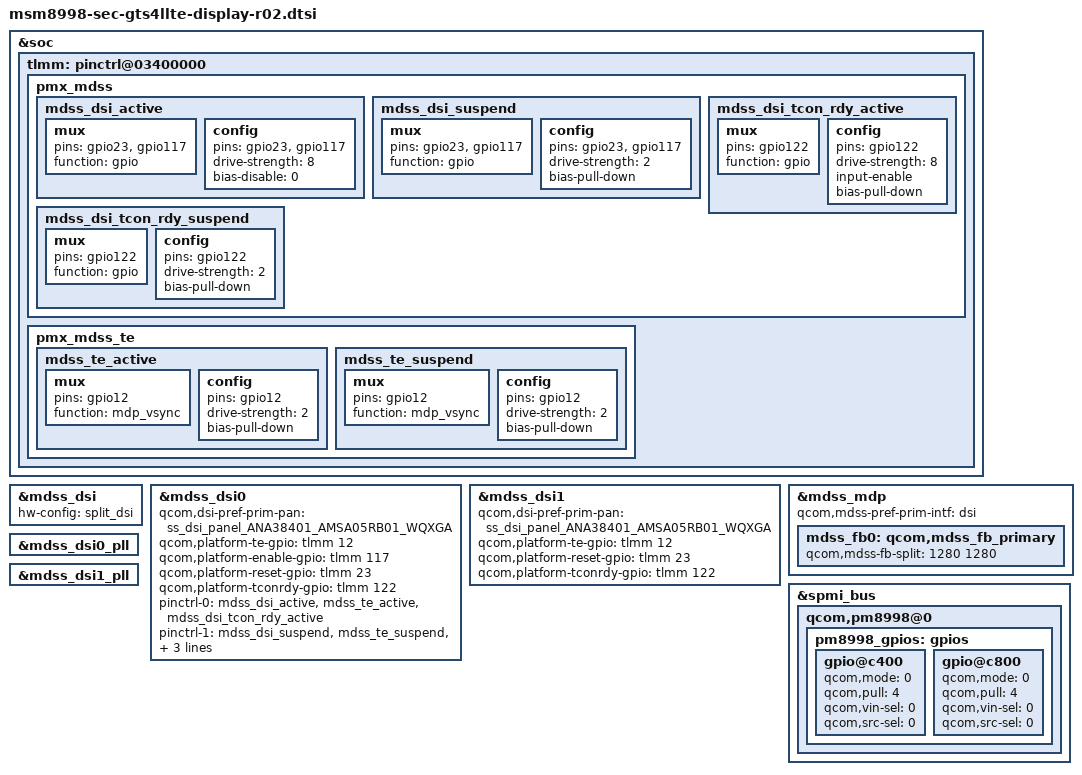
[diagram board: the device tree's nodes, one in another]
/* Copyright (c) 2016, The Linux Foundation. All rights reserved.
 *
 * This program is free software; you can redistribute it and/or modify
 * it under the terms of the GNU General Public License version 2 and
 * only version 2 as published by the Free Software Foundation.
 *
 * This program is distributed in the hope that it will be useful,
 * but WITHOUT ANY WARRANTY; without even the implied warranty of
 * MERCHANTABILITY or FITNESS FOR A PARTICULAR PURPOSE.  See the
 * GNU General Public License for more details.
 */

#include "../../../../drivers/video/fbdev/msm/samsung/ANA38401_AMSA05RB01/dsi_panel_ANA38401_AMSA05RB01_wqxga_octa_cmd.dtsi"
#include "../../../../drivers/video/fbdev/msm/samsung/PBA_BOOTING/dsi_panel_PBA_BOOTING_wqxga_video.dtsi"

/*
 * SOC Setting (TLMM Pin Control & SPI Setting)
 */

&soc {
	tlmm: pinctrl@03400000 {
		pmx_mdss: pmx_mdss {
			mdss_dsi_active: mdss_dsi_active {
				mux {
					pins = "gpio23", "gpio117";
					function = "gpio";
				};

				config {
					pins = "gpio23",  "gpio117";
					drive-strength = <8>; /* 8 mA */
					bias-disable = <0>; /* no pull */
				};
			};
			mdss_dsi_suspend: mdss_dsi_suspend {
				mux {
					pins = "gpio23",  "gpio117";
					function = "gpio";
				};

				config {
					pins = "gpio23",  "gpio117";
					drive-strength = <2>; /* 2 mA */
					bias-pull-down; /* pull down */
				};
			};

			mdss_dsi_tcon_rdy_active: mdss_dsi_tcon_rdy_active {
				mux {
					pins = "gpio122";
					function = "gpio";
				};

				config {
					pins = "gpio122";
					drive-strength = <8>; /* 8 mA */
					input-enable;
					bias-pull-down;
				};
			};
			mdss_dsi_tcon_rdy_suspend: mdss_dsi_tcon_rdy_suspend {
				mux {
					pins = "gpio122";
					function = "gpio";
				};

				config {
					pins = "gpio122";
					drive-strength = <2>; /* 2 mA */
					bias-pull-down; /* pull down */
				};
			};
		};

		pmx_mdss_te {
			mdss_te_active: mdss_te_active {
				mux {
					pins = "gpio12";
					function = "mdp_vsync";
				};
				config {
					pins = "gpio12";
					drive-strength = <2>;
					bias-pull-down;
				};
			};
			mdss_te_suspend: mdss_te_suspend {
				mux {
					pins = "gpio12";
					function = "mdp_vsync";
				};
				config {
					pins = "gpio12";
					drive-strength = <2>;
					bias-pull-down;
				};
			};
		};

	};
};

&mdss_dsi {
	hw-config = "split_dsi";  /* DSC */
};

&mdss_dsi0 {
	qcom,dsi-pref-prim-pan = <&ss_dsi_panel_ANA38401_AMSA05RB01_WQXGA>;
	qcom,platform-te-gpio = <&tlmm 12 0>;
	qcom,platform-enable-gpio = <&tlmm 117 0>;
	qcom,platform-reset-gpio = <&tlmm 23 0>;
	qcom,platform-tconrdy-gpio = <&tlmm 122 0>;

	pinctrl-names = "mdss_default", "mdss_sleep";
	pinctrl-0 = <&mdss_dsi_active &mdss_te_active &mdss_dsi_tcon_rdy_active>;
	pinctrl-1 = <&mdss_dsi_suspend &mdss_te_suspend &mdss_dsi_tcon_rdy_suspend>;
	qcom,platform-lane-config = [00 20 00 00
				00 20 00 00
				00 20 00 00
				00 20 00 00
				00 20 00 80];
};

&mdss_dsi1 {
	qcom,dsi-pref-prim-pan = <&ss_dsi_panel_ANA38401_AMSA05RB01_WQXGA>;
	qcom,platform-te-gpio = <&tlmm 12 0>;
	qcom,platform-reset-gpio = <&tlmm 23 0>;
	qcom,platform-tconrdy-gpio = <&tlmm 122 0>;
};

&mdss_mdp {
	qcom,mdss-pref-prim-intf = "dsi";
	mdss_fb0: qcom,mdss_fb_primary {
		qcom,mdss-fb-split = <1280 1280>;
	};
};

&mdss_dsi0_pll {
	/delete-property/ qcom,dsi-pll-ssc-en;
};

&mdss_dsi1_pll {
	/delete-property/qcom,dsi-pll-ssc-en;
};

/*
 * PM GPIO for Panel Status
 */

&spmi_bus {
	qcom,pm8998@0 {
		pm8998_gpios: gpios {
			gpio@c400 { /* PM8998_GPIO 5 for DISP_DET */
				status = "okay";
				qcom,mode = <0>;
				qcom,pull = <4>;
				qcom,vin-sel = <0>;
				qcom,src-sel = <0>;
			};

			gpio@c800 { /* PM8998_GPIO 9 for FG_ERR */
				status = "okay";
				qcom,mode = <0>;
				qcom,pull = <4>;
				qcom,vin-sel = <0>;
				qcom,src-sel = <0>;
			};
		};
	};
};
